# Q32M210 register map
File version: 1.0
Registers are 32-bit, read-write, no defined reset value unless marked. A register's access mark holds for its fields unless they carry their own. Offsets are from the block's base; [hi:lo] are bit positions.

## SPI1_Interface_Configuration_and_Control
Base 0x40000700
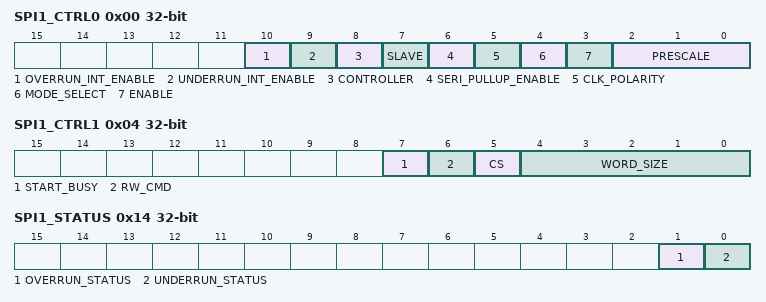
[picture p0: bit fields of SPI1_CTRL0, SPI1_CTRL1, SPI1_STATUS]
0x00 SPI1_CTRL0 — SPI1 Control and Configuration Register
  [10] OVERRUN_INT_ENABLE — Enable SPI1 overrun interrupts
    0=SPI1_OVERRUN_INT_DISABLE (No interrupts are raised when an overrun occurs on the SPI1 interface); 1=SPI1_OVERRUN_INT_ENABLE (An interrupt is raised when an overrun occurs on the SPI1 interface)
  [9] UNDERRUN_INT_ENABLE — Enable SPI1 underrun interrupts
    0=SPI1_UNDERRUN_INT_DISABLE (No interrupts are raised when an underrun occurs on the SPI1 interface); 1=SPI1_UNDERRUN_INT_ENABLE (An interrupt is raised when an underrun occurs on the SPI1 interface)
  [8] CONTROLLER — Select whether data transfer will be controlled by the ARM Cortex-M3 processor or the DMA for SPI1
    0=SPI1_CONTROLLER_CM3 (The ARM Cortex-M3 controls data transfers using SPI1); 1=SPI1_CONTROLLER_DMA (The DMA controls data transfers using SPI1)
  [7] SLAVE — Use the SPI1 interface as master or slave
    0=SPI1_SELECT_MASTER (Use the SPI1 interface in master mode); 1=SPI1_SELECT_SLAVE (Use the SPI1 interface in slave mode)
  [6] SERI_PULLUP_ENABLE — Configure the optional pull-up resistor for the SERI pad of SPI1
    0=SPI1_SERI_PULLUP_DISABLE (Disconnect the pull-up resistor from the SPI1 SERI pad); 1=SPI1_SERI_PULLUP_ENABLE (Connect a pull-up resistor to the SPI1 SERI pad)
  [5] CLK_POLARITY — Select the polarity of the SPI1 clock
    0=SPI1_CLK_POLARITY_NORMAL (SERO changes on the rising edge of SPI1 clock, SERI changes on the falling edge of SPI1 clock); 1=SPI1_CLK_POLARITY_INVERSE (SERO changes on the falling edge of SPI1 clock, SERI changes on the rising edge of SPI1 clock)
  [4] MODE_SELECT — Select between manual and auto transaction handling modes for SPI1 master transactions
    0=SPI1_MODE_SELECT_MANUAL (Master transfers using the SPI1 interface do not automatically continue); 1=SPI1_MODE_SELECT_AUTO (Automatically continue master transfers using the SPI1 interface)
  [3] ENABLE — Enable/disable the SPI1 interface
    0=SPI1_DISABLE (Disable the SPI1 interface); 1=SPI1_ENABLE (Enable the SPI1 interface)
  [2:0] PRESCALE — Prescale the SPI1 interface clock for master transfers
    0=SPI1_PRESCALE_2 (Prescale the SPI1 interface clock by 2); 1=SPI1_PRESCALE_4 (Prescale the SPI1 interface clock by 4); 2=SPI1_PRESCALE_8 (Prescale the SPI1 interface clock by 8); 3=SPI1_PRESCALE_16 (Prescale the SPI1 interface clock by 16); 4=SPI1_PRESCALE_32 (Prescale the SPI1 interface clock by 32); 5=SPI1_PRESCALE_64 (Prescale the SPI1 interface clock by 64); 6=SPI1_PRESCALE_128 (Prescale the SPI1 interface clock by 128); 7=SPI1_PRESCALE_256 (Prescale the SPI1 interface clock by 256)
0x04 SPI1_CTRL1 — SPI1 Transaction Control Register
  [7] START_BUSY — Start an SPI1 data transfer and indicate if a transfer is in progress
    0=SPI1_IDLE (Stop a transfer or indicate that the SPI1 interface is idle); 1=SPI1_START (Start a transfer on the SPI1 interface); 1=SPI1_BUSY (Indicate that the SPI1 interface is currently transferring data)
  [6] RW_CMD — Issue a read command or write command to the SPI1 interface
    0=SPI1_WRITE_DATA (Write data using the SPI1 interface); 1=SPI1_READ_DATA (Read data using the SPI1 interface)
  [5] CS — Set the chip-select line for SPI1 (master mode); read the chip-select line for SPI1 (slave mode)
    0=SPI1_CS_0 (Set the chip-select line to 0); 1=SPI1_CS_1 (Set the chip-select line to 1)
  [4:0] WORD_SIZE — Select the word size used by the SPI interface (word size = SPI1_CTRL1_WORD_SIZE + 1)
    0=SPI1_WORD_SIZE_1 (SPI transfers use 1-bit words); 7=SPI1_WORD_SIZE_8 (SPI transfers use 8-bit words); 15=SPI1_WORD_SIZE_16 (SPI transfers use 16-bit words); 23=SPI1_WORD_SIZE_24 (SPI transfers use 24-bit words); 31=SPI1_WORD_SIZE_32 (SPI transfers use 32-bit words)
0x08 SPI1_DATA
  [31:0] SPI1_DATA — Single word buffer for data to be transmitted over the SPI1 interface and data that has been received over the SPI1 interface
0x0C SPI1_DATA_S — Shadow of SPI1 Data
  [31:0] SPI1_DATA_S — "Shadow register for SPI1_DATA providing no side effect access to the interface's data"
0x10 SPI1_SLAVE_DATA — SPI1 Data for Slave Operations
  [31:0] SPI1_DATA — Single word buffer for data that has been received over the SPI1 interface when operating in slave mode
0x14 SPI1_STATUS
  [1] OVERRUN_STATUS — Indicate that an overrun has occurred when receiving data on the SPI1 interface
    0=SPI1_OVERRUN_FALSE (SPI1 no input overrun detected); 1=SPI1_OVERRUN_TRUE (SPI1 input overrun detected); 1=SPI1_OVERRUN_CLEAR (Clear the SPI1 overrun bit)
  [0] UNDERRUN_STATUS — Indicate that an underrun has occurred when transmitting data on the SPI1 interface
    0=SPI1_UNDERRUN_FALSE (SPI1 no input underrun detected); 1=SPI1_UNDERRUN_TRUE (SPI1 input underrun detected); 1=SPI1_UNDERRUN_CLEAR (Clear the SPI1 underrun bit)
